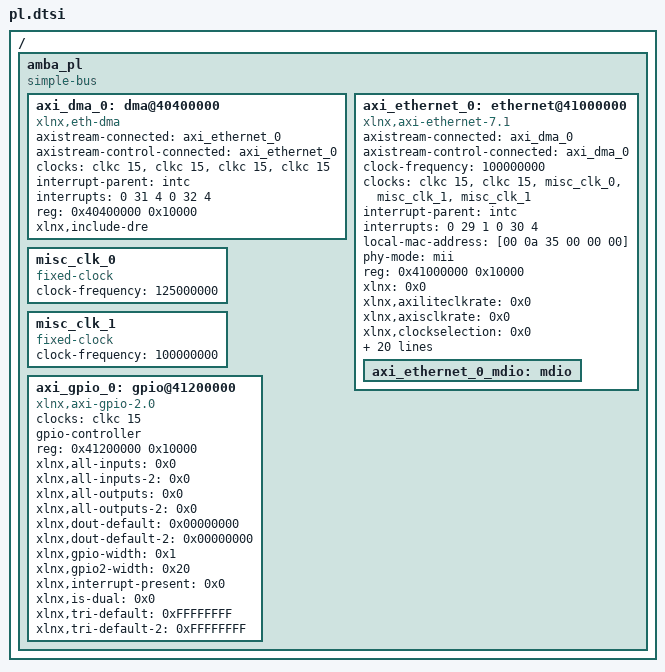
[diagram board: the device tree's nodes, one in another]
/*
 * CAUTION: This file is automatically generated by Xilinx.
 * Version:  
 * Today is: Tue Nov  8 15:11:55 2022
 */


/ {
	amba_pl: amba_pl {
		#address-cells = <1>;
		#size-cells = <1>;
		compatible = "simple-bus";
		ranges ;
		axi_dma_0: dma@40400000 {
			#dma-cells = <1>;
			axistream-connected = <&axi_ethernet_0>;
			axistream-control-connected = <&axi_ethernet_0>;
			clock-names = "s_axi_lite_aclk", "m_axi_sg_aclk", "m_axi_mm2s_aclk", "m_axi_s2mm_aclk";
			clocks = <&clkc 15>, <&clkc 15>, <&clkc 15>, <&clkc 15>;
			compatible = "xlnx,eth-dma";
			interrupt-names = "mm2s_introut", "s2mm_introut";
			interrupt-parent = <&intc>;
			interrupts = <0 31 4 0 32 4>;
			reg = <0x40400000 0x10000>;
			xlnx,include-dre ;
		};
		axi_ethernet_0: ethernet@41000000 {
			axistream-connected = <&axi_dma_0>;
			axistream-control-connected = <&axi_dma_0>;
			clock-frequency = <100000000>;
			clock-names = "s_axi_lite_clk", "axis_clk", "gtx_clk", "mii_rx_clk", "mii_tx_clk";
			clocks = <&clkc 15>, <&clkc 15>, <&misc_clk_0>, <&misc_clk_1>, <&misc_clk_1>;
			compatible = "xlnx,axi-ethernet-7.1", "xlnx,axi-ethernet-1.00.a";
			device_type = "network";
			interrupt-names = "mac_irq", "interrupt";
			interrupt-parent = <&intc>;
			interrupts = <0 29 1 0 30 4>;
			local-mac-address = [00 0a 35 00 00 00];
			phy-mode = "mii";
			reg = <0x41000000 0x10000>;
			xlnx = <0x0>;
			xlnx,axiliteclkrate = <0x0>;
			xlnx,axisclkrate = <0x0>;
			xlnx,clockselection = <0x0>;
			xlnx,enableasyncsgmii = <0x0>;
			xlnx,gt-type = <0x0>;
			xlnx,gtinex = <0x0>;
			xlnx,gtlocation = <0x0>;
			xlnx,gtrefclksrc = <0x0>;
			xlnx,include-dre ;
			xlnx,instantiatebitslice0 = <0x0>;
			xlnx,phy-type = <0x0>;
			xlnx,phyaddr = <0x1>;
			xlnx,phyrst-board-interface-dummy-port = <0x0>;
			xlnx,rable = <0x0>;
			xlnx,rxcsum = <0x0>;
			xlnx,rxlane0-placement = <0x0>;
			xlnx,rxlane1-placement = <0x0>;
			xlnx,rxmem = <0x1000>;
			xlnx,rxnibblebitslice0used = <0x0>;
			xlnx,tx-in-upper-nibble = <0x1>;
			xlnx,txcsum = <0x0>;
			xlnx,txlane0-placement = <0x0>;
			xlnx,txlane1-placement = <0x0>;
			axi_ethernet_0_mdio: mdio {
				#address-cells = <1>;
				#size-cells = <0>;
			};
		};
		misc_clk_0: misc_clk_0 {
			#clock-cells = <0>;
			clock-frequency = <125000000>;
			compatible = "fixed-clock";
		};
		misc_clk_1: misc_clk_1 {
			#clock-cells = <0>;
			clock-frequency = <100000000>;
			compatible = "fixed-clock";
		};
		axi_gpio_0: gpio@41200000 {
			#gpio-cells = <3>;
			clock-names = "s_axi_aclk";
			clocks = <&clkc 15>;
			compatible = "xlnx,axi-gpio-2.0", "xlnx,xps-gpio-1.00.a";
			gpio-controller ;
			reg = <0x41200000 0x10000>;
			xlnx,all-inputs = <0x0>;
			xlnx,all-inputs-2 = <0x0>;
			xlnx,all-outputs = <0x0>;
			xlnx,all-outputs-2 = <0x0>;
			xlnx,dout-default = <0x00000000>;
			xlnx,dout-default-2 = <0x00000000>;
			xlnx,gpio-width = <0x1>;
			xlnx,gpio2-width = <0x20>;
			xlnx,interrupt-present = <0x0>;
			xlnx,is-dual = <0x0>;
			xlnx,tri-default = <0xFFFFFFFF>;
			xlnx,tri-default-2 = <0xFFFFFFFF>;
		};
	};
};
